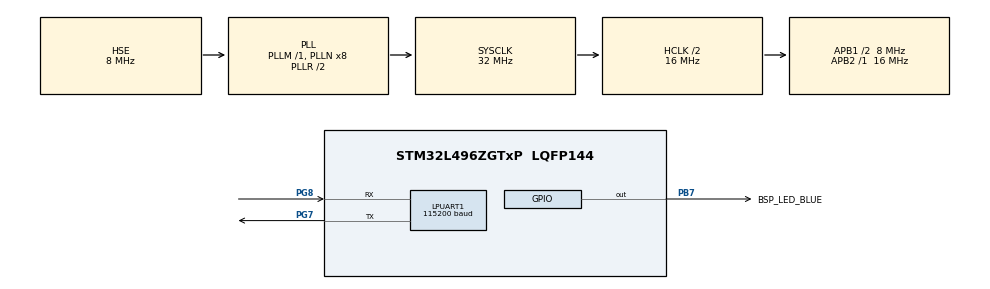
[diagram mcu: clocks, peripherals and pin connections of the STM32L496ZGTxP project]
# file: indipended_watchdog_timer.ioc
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IWDG.Prescaler=IWDG_PRESCALER_8
IWDG.Reload=79
LPUART1.BaudRate=115200
LPUART1.WordLength=UART_WORDLENGTH_8B
Mcu.Family=STM32L4
Mcu.Name=STM32L496ZGTxP
Mcu.Package=LQFP144
NVIC.PriorityGroup=NVIC_PRIORITYGROUP_4
PB7.GPIO_Label=BSP_LED_BLUE
PB7.Signal=GPIO_Output
PG7.Mode=Asynchronous
PG7.Signal=LPUART1_TX
PG8.Mode=Asynchronous
PG8.Signal=LPUART1_RX
PH0-OSC_IN\ (PH0).Mode=HSE-External-Oscillator
PH0-OSC_IN\ (PH0).Signal=RCC_OSC_IN
PH1-OSC_OUT\ (PH1).Mode=HSE-External-Oscillator
PH1-OSC_OUT\ (PH1).Signal=RCC_OSC_OUT
ProjectManager.HeapSize=0x200
ProjectManager.StackSize=0x400
ProjectManager.TargetToolchain=STM32CubeIDE
RCC.48MHZClocksFreq_Value=24000000
RCC.ADCFreq_Value=80000000
RCC.AHBCLKDivider=RCC_SYSCLK_DIV2
RCC.AHBFreq_Value=16000000
RCC.APB1CLKDivider=RCC_HCLK_DIV2
RCC.APB1Freq_Value=8000000
RCC.APB1TimFreq_Value=16000000
RCC.APB2Freq_Value=16000000
RCC.APB2TimFreq_Value=16000000
RCC.CortexFreq_Value=16000000
RCC.HCLKFreq_Value=16000000
RCC.HSE_VALUE=8000000
RCC.HSI48_VALUE=48000000
RCC.HSI_VALUE=16000000
RCC.MSI_VALUE=4000000
RCC.PLLMUL=RCC_PLL_MUL9
RCC.PLLSAI1N=20
RCC.PLLSourceVirtual=RCC_PLLSOURCE_HSE
RCC.PRESCALERUSB=RCC_USBCLKSOURCE_PLL_DIV1_5
RCC.SYSCLKFreq_VALUE=32000000
RCC.SYSCLKSource=RCC_SYSCLKSOURCE_PLLCLK
RCC.SYSCLKSourceVirtual=RCC_SYSCLKSOURCE_PLLCLK
RCC.USBFreq_Value=80000000
RCC.VCOOutputFreq_Value=64000000
VP_IWDG_VS_IWDG.Mode=IWDG_Activate
board=NUCLEO-L496ZG-P

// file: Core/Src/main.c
/* USER CODE BEGIN Header */
/**
  ******************************************************************************
  * @file           : main.c
  * @brief          : Main program body
  ******************************************************************************
  * @attention
  *
  * Copyright (c) 2023 STMicroelectronics.
  * All rights reserved.
  *
  * This software is licensed under terms that can be found in the LICENSE file
  * in the root directory of this software component.
  * If no LICENSE file comes with this software, it is provided AS-IS.
  *
  ******************************************************************************
  */
/* USER CODE END Header */
#include "main.h"

/* USER CODE BEGIN Includes */
#include"stdio.h"
#include "string.h"
/* USER CODE END Includes */

IWDG_HandleTypeDef hiwdg;

UART_HandleTypeDef hlpuart1;

void SystemClock_Config(void);
static void MX_GPIO_Init(void);
static void MX_LPUART1_UART_Init(void);
static void MX_IWDG_Init(void);

int main(void)
{

  /* MCU Configuration--------------------------------------------------------*/

  /* Reset of all peripherals, Initializes the Flash interface and the Systick. */
  HAL_Init();

  /* Configure the system clock */
  SystemClock_Config();

  /* Initialize all configured peripherals */
  MX_GPIO_Init();
  MX_LPUART1_UART_Init();
 HAL_Delay (500);
   HAL_GPIO_WritePin(BSP_LED_BLUE_GPIO_Port,BSP_LED_BLUE_Pin, 1);//SET
  MX_IWDG_Init();
  /* USER CODE BEGIN 2 */
  //printf(" Independent Watchdog test\n");

  /* USER CODE END 2 */

  /* Infinite loop */
  while (1)
  {

    /* USER CODE BEGIN 3 */
	  HAL_Delay(18);//used time between 0 to 18
	  HAL_IWDG_Refresh(&hiwdg);

  }
  /* USER CODE END 3 */
}

void SystemClock_Config(void)
{
  RCC_OscInitTypeDef RCC_OscInitStruct = {0};
  RCC_ClkInitTypeDef RCC_ClkInitStruct = {0};

  /** Configure the main internal regulator output voltage
  */
  if (HAL_PWREx_ControlVoltageScaling(PWR_REGULATOR_VOLTAGE_SCALE1) != HAL_OK)
  {
    Error_Handler();
  }

  /** Initializes the RCC Oscillators according to the specified parameters
  * in the RCC_OscInitTypeDef structure.
  */
  RCC_OscInitStruct.OscillatorType = RCC_OSCILLATORTYPE_LSI|RCC_OSCILLATORTYPE_HSE;
  RCC_OscInitStruct.HSEState = RCC_HSE_ON;
  RCC_OscInitStruct.LSIState = RCC_LSI_ON;
  RCC_OscInitStruct.PLL.PLLState = RCC_PLL_ON;
  RCC_OscInitStruct.PLL.PLLSource = RCC_PLLSOURCE_HSE;
  RCC_OscInitStruct.PLL.PLLM = 1;
  RCC_OscInitStruct.PLL.PLLN = 8;
  RCC_OscInitStruct.PLL.PLLP = RCC_PLLP_DIV2;
  RCC_OscInitStruct.PLL.PLLQ = RCC_PLLQ_DIV2;
  RCC_OscInitStruct.PLL.PLLR = RCC_PLLR_DIV2;
  if (HAL_RCC_OscConfig(&RCC_OscInitStruct) != HAL_OK)
  {
    Error_Handler();
  }

  /** Initializes the CPU, AHB and APB buses clocks
  */
  RCC_ClkInitStruct.ClockType = RCC_CLOCKTYPE_HCLK|RCC_CLOCKTYPE_SYSCLK
                              |RCC_CLOCKTYPE_PCLK1|RCC_CLOCKTYPE_PCLK2;
  RCC_ClkInitStruct.SYSCLKSource = RCC_SYSCLKSOURCE_PLLCLK;
  RCC_ClkInitStruct.AHBCLKDivider = RCC_SYSCLK_DIV2;
  RCC_ClkInitStruct.APB1CLKDivider = RCC_HCLK_DIV2;
  RCC_ClkInitStruct.APB2CLKDivider = RCC_HCLK_DIV1;

  if (HAL_RCC_ClockConfig(&RCC_ClkInitStruct, FLASH_LATENCY_0) != HAL_OK)
  {
    Error_Handler();
  }
}

static void MX_IWDG_Init(void)
{

  hiwdg.Instance = IWDG;
  hiwdg.Init.Prescaler = IWDG_PRESCALER_8;
  hiwdg.Init.Window = 4095;
  hiwdg.Init.Reload = 79;
  if (HAL_IWDG_Init(&hiwdg) != HAL_OK)
  {
    Error_Handler();
  }

}

static void MX_LPUART1_UART_Init(void)
{

  hlpuart1.Instance = LPUART1;
  hlpuart1.Init.BaudRate = 115200;
  hlpuart1.Init.WordLength = UART_WORDLENGTH_8B;
  hlpuart1.Init.StopBits = UART_STOPBITS_1;
  hlpuart1.Init.Parity = UART_PARITY_NONE;
  hlpuart1.Init.Mode = UART_MODE_TX_RX;
  hlpuart1.Init.HwFlowCtl = UART_HWCONTROL_NONE;
  hlpuart1.Init.OneBitSampling = UART_ONE_BIT_SAMPLE_DISABLE;
  hlpuart1.AdvancedInit.AdvFeatureInit = UART_ADVFEATURE_NO_INIT;
  if (HAL_UART_Init(&hlpuart1) != HAL_OK)
  {
    Error_Handler();
  }

}

static void MX_GPIO_Init(void)
{
  GPIO_InitTypeDef GPIO_InitStruct = {0};

  /* GPIO Ports Clock Enable */
  __HAL_RCC_GPIOH_CLK_ENABLE();
  __HAL_RCC_GPIOG_CLK_ENABLE();
  HAL_PWREx_EnableVddIO2();
  __HAL_RCC_GPIOB_CLK_ENABLE();

  /*Configure GPIO pin Output Level */
  HAL_GPIO_WritePin(BSP_LED_BLUE_GPIO_Port, BSP_LED_BLUE_Pin, GPIO_PIN_RESET);

  /*Configure GPIO pin : BSP_LED_BLUE_Pin */
  GPIO_InitStruct.Pin = BSP_LED_BLUE_Pin;
  GPIO_InitStruct.Mode = GPIO_MODE_OUTPUT_PP;
  GPIO_InitStruct.Pull = GPIO_NOPULL;
  GPIO_InitStruct.Speed = GPIO_SPEED_FREQ_LOW;
  HAL_GPIO_Init(BSP_LED_BLUE_GPIO_Port, &GPIO_InitStruct);

}

void Error_Handler(void)
{
  __disable_irq();
  while (1)
  {
  }
}
